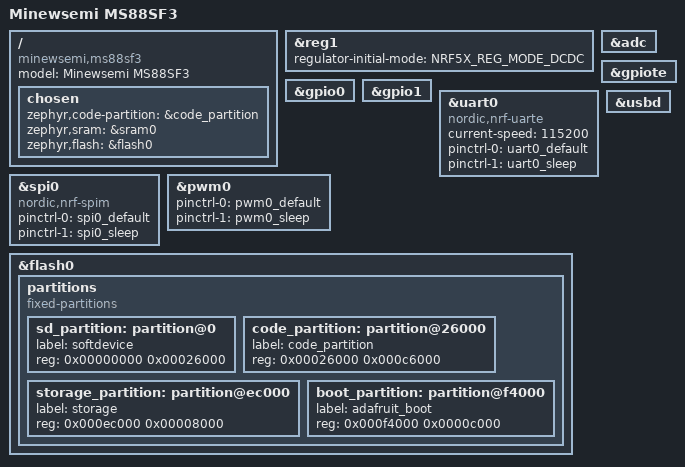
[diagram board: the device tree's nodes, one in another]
/*
 * Copyright (c) 2026 EKS Inc.
 * Created by Ryu.
 * SPDX-License-Identifier: LicenseRef-EKS-NonCommercial-1.0
 */

/dts-v1/;
#include <nordic/nrf52840_qiaa.dtsi>
#include <common/nordic/nrf52840_uf2_boot_mode.dtsi>
#include "ms88sf3_nrf52840-pinctrl.dtsi"

/ {
	model = "Minewsemi MS88SF3";
	compatible = "minewsemi,ms88sf3";

	chosen {
		zephyr,code-partition = &code_partition;
		zephyr,sram = &sram0;
		zephyr,flash = &flash0;
	};
};

&reg1 {
	regulator-initial-mode = <NRF5X_REG_MODE_DCDC>;
};

&adc {
	status = "okay";
};

&gpiote {
	status = "okay";
};

&gpio0 {
	status = "okay";
};

&gpio1 {
	status = "okay";
};

&uart0 {
	compatible = "nordic,nrf-uarte";
	current-speed = <115200>;
	pinctrl-0 = <&uart0_default>;
	pinctrl-1 = <&uart0_sleep>;
	pinctrl-names = "default", "sleep";
};

&spi0 {
	compatible = "nordic,nrf-spim";
	pinctrl-0 = <&spi0_default>;
	pinctrl-1 = <&spi0_sleep>;
	pinctrl-names = "default", "sleep";
};

&pwm0 {
	status = "okay";
	pinctrl-0 = <&pwm0_default>;
	pinctrl-1 = <&pwm0_sleep>;
	pinctrl-names = "default", "sleep";
};

zephyr_udc0: &usbd {
	status = "okay";
};

/*
 * Flash layout matches nice!nano v2 so prebuilt ZMK UF2 tooling stays compatible
 * with the Adafruit nRF52 bootloader (UF2) flashed at 0xF4000.
 *
 *   0x00000 - 0x26000  MBR + reserved softdevice slot (unused by ZMK)
 *   0x26000 - 0xEC000  application (code_partition, linked here)
 *   0xEC000 - 0xF4000  storage_partition (32 KB NVS: BLE bonds, settings)
 *   0xF4000 - 0x100000 Adafruit bootloader (40 KB) + MBR params + boot settings
 */
&flash0 {
	partitions {
		compatible = "fixed-partitions";
		#address-cells = <1>;
		#size-cells = <1>;

		sd_partition: partition@0 {
			label = "softdevice";
			reg = <0x00000000 0x00026000>;
		};
		code_partition: partition@26000 {
			label = "code_partition";
			reg = <0x00026000 0x000c6000>;
		};
		storage_partition: partition@ec000 {
			label = "storage";
			reg = <0x000ec000 0x00008000>;
		};
		boot_partition: partition@f4000 {
			label = "adafruit_boot";
			reg = <0x000f4000 0x0000c000>;
		};
	};
};
